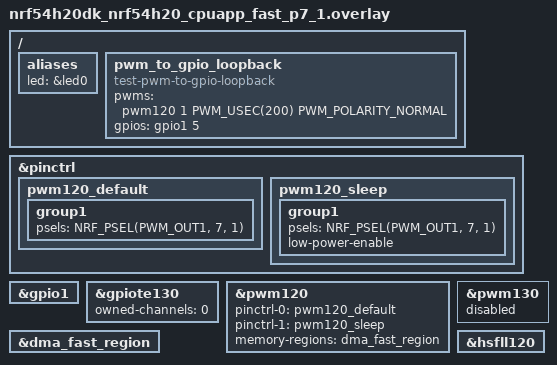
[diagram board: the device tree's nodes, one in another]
/*
 * Copyright (c) 2024 Nordic Semiconductor ASA
 *
 * SPDX-License-Identifier: LicenseRef-Nordic-5-Clause
 */

#include <zephyr/dt-bindings/pwm/pwm.h>
#include <zephyr/dt-bindings/gpio/nordic-nrf-gpio.h>

/* Test requires wire connection between:
 *  - PWM120 OUT[1] at P7.01
 *  - GPIO input at P1.05
 */

/ {
	aliases {
		led = &led0;
		/delete-property/ led1;
	};

	pwm_to_gpio_loopback: pwm_to_gpio_loopback {
		compatible = "test-pwm-to-gpio-loopback";
		pwms = <&pwm120 1 PWM_USEC(200) PWM_POLARITY_NORMAL>;
		gpios = <&gpio1 5 GPIO_ACTIVE_HIGH>;
	};
};

/delete-node/ &led1;

&pinctrl {
	/omit-if-no-ref/ pwm120_default: pwm120_default {
		group1 {
			psels = <NRF_PSEL(PWM_OUT1, 7, 1)>;
		};
	};
	/omit-if-no-ref/ pwm120_sleep: pwm120_sleep {
		group1 {
			psels = <NRF_PSEL(PWM_OUT1, 7, 1)>;
			low-power-enable;
		};
	};
};

&gpio1 {
	status = "okay";
};

&gpiote130 {
	status = "okay";
	owned-channels = <0>;
};

&pwm120 {
	status = "okay";
	pinctrl-0 = <&pwm120_default>;
	pinctrl-1 = <&pwm120_sleep>;
	pinctrl-names = "default", "sleep";
	memory-regions = <&dma_fast_region>;
};

&dma_fast_region {
	status = "okay";
};

&pwm130 {
	status = "disabled";
};

&hsfll120 {
	status = "okay";
};
